# YTM32B1ME1 register map
Vendor: YTMicro; File version: 1.0
CPU: CM33 r0p4, little endian, MPU, FPU, 2 interrupt priority bits
Registers are 32-bit, read-write, reset 0x0 unless marked. A register's access mark holds for its fields unless they carry their own. Offsets are from the block's base; [hi:lo] are bit positions; {n}, {i} and the like mark numbered series; 'fields as' and 'values as' point back to an identical list.

## eTMR0 — Enhanced timer
Base 0x40124000; register names take the prefix eTMR0_
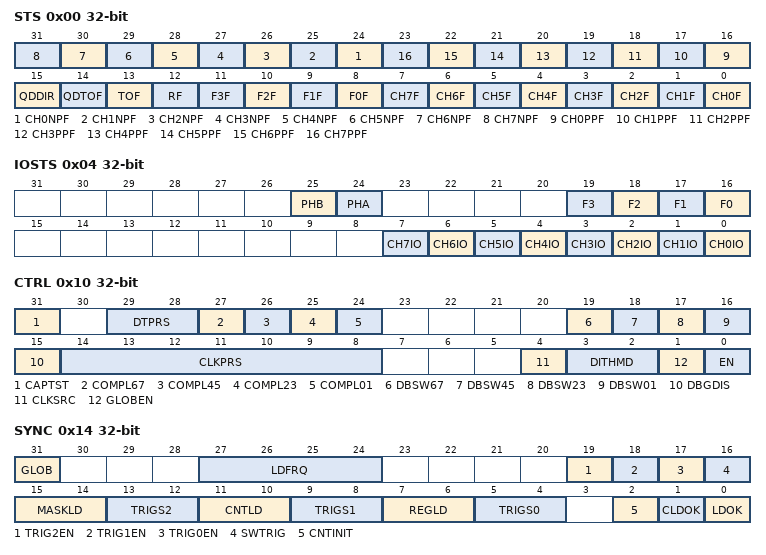
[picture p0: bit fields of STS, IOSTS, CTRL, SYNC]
0x00 STS
  [n+24] CH{n}NPF (n=0..7) — Capture negative pulse ready flag, write 1 to clear this bit.
  [n+16] CH{n}PPF (n=0..7) — Capture positive pulse ready flag, write 1 to clear this bit.
  [15] QDDIR ro — Indicate quadrature decoder counter direction.
    0=Quadrature counter increase; 1=Quadrature counter decrease
  [14] QDTOF — When STS[QDTOF]=1, STS[QDDIR]=0, means quadrature decoder counter increase to QDMOD[QDMOD], then overflow to QDINIT[QDINIT]. When STS[QDTOF]=1, STS[QDDIR]=1, means quadrature decoder counter decrease to QDINIT[QDINIT], then overflow to QDMOD[QDMOD]. Write 1 to clear the bit.
  [13] TOF — Timer overflow flag sets when counter increase from MOD[MOD] to INIT[INIT]. Write 1 to clear the bit.
  [12] RF — Reload flag sets when registers loading occurs. write 1 to clear the bit.
  [n+8] F{n}F (n=0..3) — Fault event {n} occurs flag. Write 1 to clear the bit.
  [n] CH{n}F (n=0..7) — Channel {n} flag is used for capture mode and compare mode. In capture mode, this flag sets when capture event occurs. In compare mode, this flag sets when counter matches the values. Write 1 to clear the bit.
0x04 IOSTS ro
  [25] PHB — Phase B input status is used for Quadrature Decoder. Read-only.
  [24] PHA — Phase A input status is used for Quadrature Decoder. Read-only.
  [n+16] F{n} (n=0..3) — Fault {n} input status is used for fault logic. Read-only.
  [n] CH{n}IO (n=0..7) — In capture mode or common mode, indicate channel {n} input status. In compare mode or PWM mode, indicate channel {n} output status. Read-only.
0x08 CNT
  [31:0] CNT — When CTRL[EN]=0, writing to this register initializes counter according to SYNC[CNTINIT] configuration. When CTRL[EN]=1, reading this register gets the counter value, and writing to this register reloads value from INIT.
0x0C QDCNT ro
  [15:0] QDCNT — Reading this register gets quadrature decoder counter value. The write operation is not valid.
0x10 CTRL
  [31] CAPTST — This bit is used for the capture test.
    0=Capture test is disabled; 1=Capture test is enabled
  [29:28] DTPRS — Clock prescaler for deadtime counter, from 1 to 4.
  [27] COMPL67 — Channel 6 and 7 output independently or complementary in PWM mode.
    0=Independent mode; 1=Complementary mode
  [26] COMPL45 — Channel 4 and 5 output independently or complementary in PWM mode.
    0=Independent mode; 1=Complementary mode
  [25] COMPL23 — Channel 2 and 3 output independently or complementary in PWM mode.
    0=Independent mode; 1=Complementary mode
  [24] COMPL01 — Channel 0 and 1 output independently or complementary in PWM mode.
    0=Independent mode; 1=Complementary mode
  [19] DBSW67 — Channel 6 and 7 is used to generate the double switch signal.
    0=Double switch is disabled; 1=Double switch is enabled
  [18] DBSW45 — Channel 4 and 5 is used to generate the double switch signal.
    0=Double switch is disabled; 1=Double switch is enabled
  [17] DBSW23 — Channel 2 and 3 is used to generate the double switch signal.
    0=Double switch is disabled; 1=Double switch is enabled
  [16] DBSW01 — Channel 0 and 1 is used to generate the double switch signal.
    0=Double switch is disabled; 1=Double switch is enabled
  [15] DBGDIS — Enable/disable the debug mode control.
    0=Counter stops under debug mode; 1=Counter keeps running under debug mode
  [14:8] CLKPRS — Clock prescaler for counter, from 1 to 128.
  [4] CLKSRC — Clock source for counter, bus clock or external clock.
    0=Select bus clock; 1=Select external clock
  [3:2] DITHMD — Select the dithering type in PWM mode.
    0=The dithering mode is disabled; 1=Select period dithering; 2=Select edge dithering; 3=Select period and edge dithering
  [1] GLOBEN — eTMRs counter synchronization mechanisms.
    0=Global logic is disabled; 1=Global logic is enabled. When SYNC[GLOB]=1 from any eTMR includes itself, the counter starts running. When all eTMRs includes itself SYNC[GLOB]=0, the counter stops.
  [0] EN — eTMR enable/disable.
    0=The eTMR is disabled; 1=The eTMR is enabled
0x14 SYNC
  [31] GLOB — Generate global base signal. This bit is used to synchronize with other eTMRs which CTRL[GLOBEN]=1.
    0=Not generate global base signal; 1=Generate global base signal
  [27:24] LDFRQ — Registers Loading occurs at the reloading opportunity that meets this specified frequency.
  [19] TRIG2EN — Enable hardware trigger 2.
    0=Hardware trigger 2 is disabled; 1=Hardware trigger 2 is enabled
  [18] TRIG1EN — Enable hardware trigger 1.
    0=Hardware trigger 1 is disabled; 1=Hardware trigger 1 is enabled
  [17] TRIG0EN — Enable hardware trigger 0.
    0=Hardware trigger 0 is disabled; 1=Hardware trigger 0 is enabled
  [16] SWTRIG wo — Software trigger is used for relevant registers loading. Writing 1 to this bit generates one bus clock cycle pulse trigger. Write-only.
  [15:14] MASKLD — Select loading opportunity for CHMASK register.
    0=Loading together with registers (INIT, MID, MOD, CH_VAL0 and CH_VAL1); 1=Loading occurs when counter matches with MOD[MOD]; 2=Loading occurs when counter matches with MID[MID]; 3=Loading occurs with trigger event which selected by SYNC[TRIGS2]. Any valid hardware trigger x will generate a trigger event (x=0,1,2).
  [13:12] TRIGS2 — Select the loading trigger source for CHMASK register. When selecting hardware trigger, any trigger enabled by SYNC[TRIGxEN] configuratgion is as valid trigger source.
    0=Disable trigger; 1=Select software trigger; 2=Select hardware trigger; 3=Software and hardware trigger are both valid
  [11:10] CNTLD — Select loading opportunity for counter, the counter loads with value from INIT +1.
    0=Loading together with registers (INIT, MID, MOD, CH_VAL0 and CH_VAL1); 1=Loading occurs when counter matches with MID[MID]; 2=Loading occurs with trigger event which selected by SYNC[TRIGS1]. Any valid hardware trigger x will generate a trigger event (x=0,1,2).
  [9:8] TRIGS1 — Select the loading trigger source for counter. When selecting hardware trigger, any trigger enabled by SYNC[TRIGxEN] configuratgion is as valid trigger source.
    values as TRIGS2
  [7:6] REGLD — Select loading opportunity for registers (INIT, MID, MOD, CH_VAL0, CH_VAL1).
    0=Loading is disabled; 1=Loading occurs when counter matches with MOD[MOD]; 2=Loading occurs when counter matches with MID[MID]; 3=Loading occurs with trigger event which selected by SYNC[TRIGS0]. Any valid hardware trigger x will generate a trigger event (x=0,1,2).
  [5:4] TRIGS0 — Select the loading trigger source for registers (INIT, MOD, MID, CH_VAL0, CH_VAL1). When selecting hardware trigger, any trigger enabled by SYNC[TRIGxEN] configuratgion is as valid trigger source.
    values as TRIGS2
  [2] CNTINIT — Before the eTMR enables, select initial value source for counter.
    0=Counter initial value is from register CNT by writing operation; 1=Counter initial value is from register INIT
  [1] CLDOK — Write 1 to this bit to clear SYNC[LDOK], and it automatically clear when SYNC[LDOK]=0.
  [0] LDOK — Set LDOK=1 to indicate registers (INIT, MID, MOD, CH_VAL0, CH_VAL1) loading is ready, it automatically clear when registers loading successfully.
    0=Registers loading is not ready; 1=Registers loading is ready and waits for loading opportunity
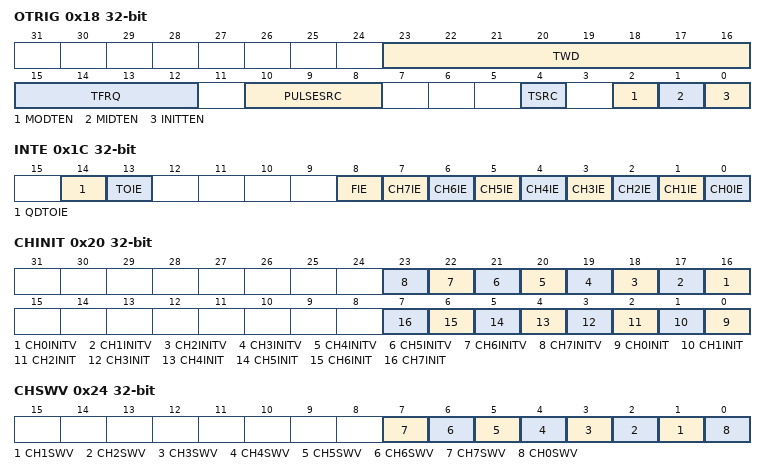
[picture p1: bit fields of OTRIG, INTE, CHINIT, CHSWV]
0x18 OTRIG
  [23:16] TWD — Trigger output width configurable from 1 to 256 bus clock cycles. Default trigger width is 1 bus clock cycle.
  [15:12] TFRQ — Trigger output occurs at the opportunity that meets the specified frequency.
  [10:8] PULSESRC — Select PWM as the pulse-out signal.
    {v}=Select channel {v} PWM as the pulse-out signal (v=0..6); 7=select channel 7 PWM as the pulse-out signal
  [4] TSRC — Trigger output source: matching event occurs or PWM output.
    0=Select trigger that generated by matching event; 1=Select PWM output as the trigger
  [2] MODTEN — Enable/disable the MOD[MOD] matching trigger.
    0=Not generate trigger when counter matches with MOD[MOD]; 1=Generate trigger when counter matches with MOD[MOD]
  [1] MIDTEN — Enable/disable the MID[MID] matching trigger.
    0=Not generate trigger when counter matches with MID[MID]; 1=Generate trigger when counter matches with MID[MID]
  [0] INITTEN — Enable/disable the INIT[INIT] matching trigger.
    0=Not generate trigger when counter matches with INIT[INIT] + 1; 1=Generate trigger when counter matches with INIT[INIT] + 1
0x1C INTE
  [14] QDTOIE — Quadrature decoder timer overflow interrupt enable/disable.
    0=Quadrature decoder timer overflow interrupt is disabled; 1=Quadrature decoder timer overflow interrupt is enabled
  [13] TOIE — Timer overflow interrupt enable/disable.
    0=Timer overflow interrupt is disabled; 1=Timer overflow interrupt is enabled
  [8] FIE — Fault interrupt enable/disable.
    0=Fault interrupt is disabled; 1=Fault interrupt is enabled
  [n] CH{n}IE (n=0..7) — Channel {n} capture/compare interrupt enable/disable.
    0=Channel {n} interrupt is disabled; 1=Channel {n} interrupt is enabled
0x20 CHINIT
  [n+16] CH{n}INITV (n=0..7) — Channel {n} output initial value.
    0=Channel {n} output initial value is 0; 1=Channel {n} output initial value is 1
  [n] CH{n}INIT wo (n=0..7) — Write 1 to this bit to initialize channel output with CHINIT[CH{n}INITV], channel output change with a counter matching event. Write-Only.
    0=Channel {n} output not initial; 1=Channel {n} output initial
0x24 CHSWV
  [n] CH{n}SWV (n=1..7) — Channel {n} output value configured by software.
    0=Channel {n} output value forced to 0 by software; 1=Channel {n} output value forced to 1 by software
  [0] CH0SWV — Channel 0 forced value by software.
    0=Channel 0 output value forced to 0 by software; 1=Channel 0 output value forced to 1 by software
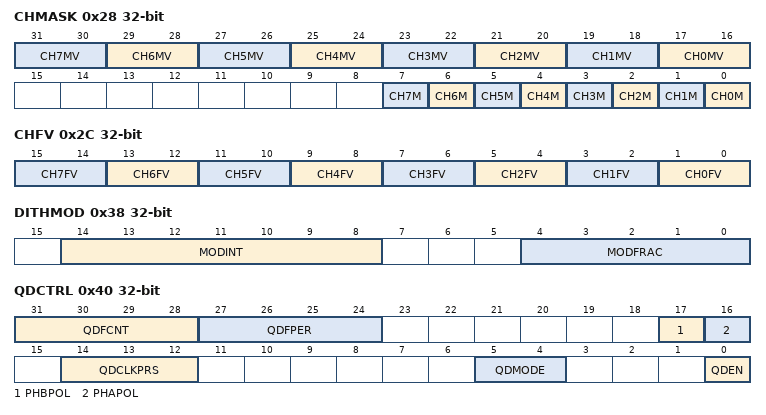
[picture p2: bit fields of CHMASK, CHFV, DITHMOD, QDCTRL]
0x28 CHMASK
  [2n+17:2n+16] CH{n}MV (n=0..7) — Define channel {n} output mask value, it's enabled when CHMASK[CH{n}M]=1.
    0=Channel {n} output mask value is 0; 1=Channel {n} output mask value is 1; 2=Channel {n} output mask value is tri-state; 3=Channel {n} output mask value is tri-state
  [n] CH{n}M (n=0..7) — Channel {n} output mask control used for PWM mode.
    0=Channel {n} output PWM normally; 1=Channel {n} output masked by CHMASK[CH{n}MV]
0x2C CHFV
  [2n+1:2n] CH{n}FV (n=0..7) — Channel {n} forced value when fault event occurs.
    0=Channel {n} output value forced to 0; 1=Channel {n} output value forced to 1; 2=Channel {n} output value forced to tri-state; 3=Channel {n} output value forced to tri-state
0x30 INIT — This register is 32-bit valid in eTMR3, and 16-bit in other instances.
  [31:0] INIT — Counter initial value
0x34 MOD reset 0xFFFF — This register is 32-bit valid in eTMR3, and 16-bit in other instances. Since the counter is 32-bit in eTMR3. The default value is 0xFFFFFFFF in eTMR3, 0x0000FFFF in other eTMRs.
  [31:0] MOD — Counter modulus value.
0x38 DITHMOD
  [14:8] MODINT — The integer part used for period dithering.
  [4:0] MODFRAC — The fractional part used for period dithering.
0x3C MID reset 0xFF — This register is 32-bit valid in eTMR3, and 16-bit in other instances. The default value is 0x0000FFFF in eTMR3, others' are 0x000000FF.
  [31:0] MID — Counter middle value.
0x40 QDCTRL
  [31:28] QDFCNT — Quadrature decoder phase A and phase B input filter sample count, the input is ignored when its valid width was less than QDFCNT x QDFPER.
  [27:24] QDFPER — Quadrature decoder phase A and phase B input filter sample period, the input is ignored when its valid width was less than QDFCNT x QDFPER.
  [17] PHBPOL — Phase B polarity selection.
    0=Not invert phase B input; 1=Invert phase B input
  [16] PHAPOL — Phase A polarity selection.
    0=Not invert phase A input; 1=Invert phase A input
  [14:12] QDCLKPRS — Clock prescaler for quadrature decoder counter.
    0=Divided by 1; 1=Divided by 2; 2=Divided by 4; 3=Divided by 8; 4=Divided by 16; 5=Divided by 32; 6=Divided by 64; 7=Divided by 128
  [5:4] QDMODE — Select decoding mode in the quadrature decoder mode.
    0=Phase A and phase B decoding mode. When phase B changes follow phase A, the counter increases. When phase A changes follow phase B, the counter decreases.; 1=Phase A and phase B decoding mode. When phase A changes follow phase B, the counter increases. When phase B changes follow phase A, the counter decreases.; 2=Counting and direction decoding mode. Phase B input controls direction. When phase B input is high, the counter increases with phase A pulse. When phase B input is low, the counter decreases with phase A pulse.; 3=Counting and direction decoding mode. Phase A input controls direction. When phase A input is high, the counter increases with phase B pulse. When phase A input is low, the counter decreases with phase B pulse.
  [0] QDEN — Quadrature decoder enable/disable.
    0=Quadrature decoder is disabled; 1=Quadrature decoder is enabled
0x44 QDINIT
  [15:0] QDINIT — Quadrature decoder counter initial value.
0x48 QDMOD reset 0xFFFF — The default value is 0x0000FFFF in eTMR1 and eTMR2, others are 0x00000000.
  [15:0] QDMOD — Quadrature decoder counter Modulus value.
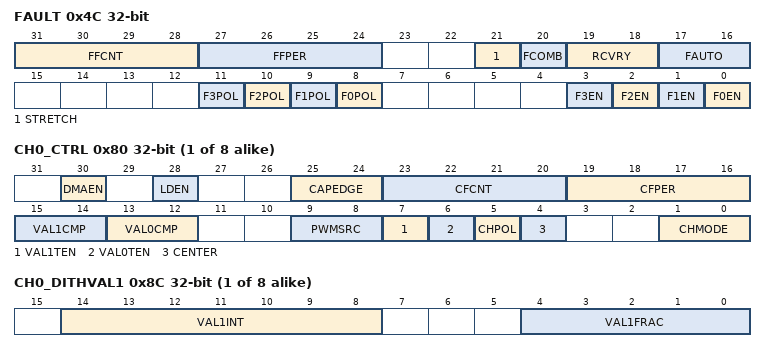
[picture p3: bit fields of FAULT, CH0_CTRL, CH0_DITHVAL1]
0x4C FAULT
  [31:28] FFCNT — Fault input filter sample count, the input is ignored when its valid width was less than FFCNT x FFPER.
  [27:24] FFPER — Fault input filter sample period, the input is ignored when its valid width was less than FFCNT x FFPER.
  [21] STRETCH — Fault input stretch to 2 bus clock cycles width at least.
  [20] FCOMB — When there is no bus clock, the fault event is generated by the combinational logic circuit.
    0=Fault combinational logic disable; 1=Fault combinational logic enable
  [19:18] RCVRY — Select PWM recovery opportunity after fault revoke.
    0=PWM recovery is disabled; 1=PWM can recover when counter matches with MID[MID]; 2=PWM can recover when counter matches with MOD[MOD]; 3=PWM can recover immediately
  [17:16] FAUTO — Select fault automatic recovery mode after the fault event end.
    0=After clearing STS[FxF] flag manually, the fault recovers automatically; 1=The fault recovers immediately, not care STS[FxF] flag; 2=The fault recovers immediately and STS[FxF] flag clear automatically
  [n+8] F{n}POL (n=0..3) — Fault {n} input polarity selection.
    0=High level signal is regarded as fault signal; 1=Invert fault {n} input. Low level signal is regarded as fault signal.
  [n] F{n}EN (n=0..3) — Fault {n} enable.
    0=Fault {n} disable; 1=Fault {n} enable
{0x80+0x40*i} CH{i}_CTRL (i=0..7)
  [30] DMAEN — DMA enable/disable for compare/capture mode.
    0=DMA is disabled; 1=DMA is enabled
  [28] LDEN — Current channel registers (CH_VAL0/CH_VAL1) loading enable/disable.
    0=Registers Loading is disabled; 1=Registers Loading is enabled
  [25:24] CAPEDGE — Select the capture edge in the input capture mode.
    0=Capture is disabled; 1=Capture rising edge; 2=Capture falling edge; 3=Capture both rising edge and falling edge
  [23:20] CFCNT — Capture input filter sample counter, the input is ignored when its valid width was less than CFCNT x CFPER.
  [19:16] CFPER — Capture input filter sample period, the input is ignored when its valid width was less than CFCNT x CFPER.
  [15:14] VAL1CMP — Select the output value when counter matches with CH_VAL1[VAL1] in compare mode.
    0=Output value 0 when counter matches with CH_VAL1[VAL1]; 1=Output value 1 when counter matches with CH_VAL1[VAL1]; 2=Output toggle when counter matches with CH_VAL1[VAL1]
  [13:12] VAL0CMP — Select the output value when counter matches with CH_VAL0[VAL0] in compare mode.
    0=Output value 0 when counter matches with CH_VAL0[VAL0]; 1=Output value 1 when counter matches with CH_VAL0[VAL0]; 2=Output toggle when counter matches with CH_VAL0[VAL0]
  [9:8] PWMSRC — Select PWM generation source in PWM mode.
    0=Normal mode, PWM is generated by VAL0 and VAL1; 1=Invert mode, invert the PWM in normal mode; 2=Software mode, PWM is generated by CHSWV register
  [7] VAL1TEN — Enable/disable generating trigger when counter matches with CH_VAL1[VAL1].
    0=Not generate trigger when counter matches with CH_VAL1[VAL1]; 1=Generate trigger when counter matches with CH_VAL1[VAL1]
  [6] VAL0TEN — Enable/disable generating trigger when counter matches with CH_VAL0[VAL0].
    0=Not generate trigger when counter matches with CH_VAL0[VAL0]; 1=Generate trigger when counter matches with CH_VAL0[VAL0]
  [5] CHPOL — Channel output polarity control.
    0=Not invert the channel output; 1=Invert the channel output
  [4] CENTER — Center aligned PWM generate when center aligned mode enabled.
    0=Center aligned mode disabled; 1=Center aligned mode enabled
  [1:0] CHMODE — Select channel mode.
    0=Common timer; 1=PWM mode; 2=Compare mode; 3=Capture mode
{0x84+0x40*i} CH{i}_VAL0 (i=0..7) — This register is 32-bit valid in eTMR3. Other eTMRs are 16-bit valid.
  [31:0] VAL0 — Define the value 0.
{0x88+0x40*i} CH{i}_VAL1 (i=0..7) — This register is 32-bit valid in eTMR3. Other eTMRs are 16-bit valid.
  [31:0] VAL1 — Define the value 1.
{0x8C+0x40*i} CH{i}_DITHVAL1 (i=0..7)
  [14:8] VAL1INT — The integer part used for duty cycle dithering.
  [4:0] VAL1FRAC — The fractional part used for duty cycle dithering.
{0x90+0x40*i} CH{i}_DT (i=0..7)
  [15:0] DTVAL — Deatime value used in complementary mode.
{0x94+0x40*i} CH{i}_CVAL ro (i=0..7) — This register is 32-bit valid in eTMR3. Other eTMRs are 16-bit valid.
  [31:0] CVAL — In capture mode, store counter value when a capture event occurs.
{0x98+0x40*i} CH{i}_PPCNTN ro (i=0..7) — This register is 32-bit valid in eTMR3, other eTMRs are 16-bit valid.
  [7:0] PPCNTN — Positive pulse width measurement counter period number.
{0x9C+0x40*i} CH{i}_PPCNTV ro (i=0..7) — This register is 32-bit valid in eTMR3, other eTMRs are 16-bit valid.
  [31:0] PPCNTV — Positive pulse width measurement capture counter value.
{0xA0+0x40*i} CH{i}_NPCNTN ro (i=0..7) — This register is 32-bit valid in eTMR3, other eTMRs are 16-bit valid.
  [7:0] NPCNTN — Negative pulse width measurement counter period number.
{0xA4+0x40*i} CH{i}_NPCNTV ro (i=0..7) — This register is 32-bit valid in eTMR3, other eTMRs are 16-bit valid.
  [31:0] NPCNTV — Negative pulse width measurement capture counter value.

## eTMR1 — Enhanced timer
Base 0x40128000; register names take the prefix eTMR1_
Registers as eTMR0; these are added or differ:
0x48 QDMOD reset 0xFFFF — The default value is 0x0000FFFF in eTMR1 and eTMR2, others are 0x00000000.
  [15:0] QDMOD — Quadrature decoder counter Modulus value.

## eTMR2 — Enhanced timer
Base 0x4012C000; register names take the prefix eTMR2_
Registers as eTMR0; these are added or differ:
0x48 QDMOD reset 0xFFFF — The default value is 0x0000FFFF in eTMR1 and eTMR2, others are 0x00000000.
  [15:0] QDMOD — Quadrature decoder counter Modulus value.

## eTMR3 — Enhanced timer
Base 0x40130000; register names take the prefix eTMR3_
Registers as eTMR0; these are added or differ:
0x30 INIT — This register is 32-bit valid in eTMR3, and 16-bit in other instances.
  [31:0] INIT — Counter initial value
0x34 MOD reset 0xFFFF — This register is 32-bit valid in eTMR3, and 16-bit in other instances. Since the counter is 32-bit in eTMR3. The default value is 0xFFFFFFFF in eTMR3, 0x0000FFFF in other eTMRs.
  [31:0] MOD — Counter modulus value.
0x3C MID reset 0xFF — This register is 32-bit valid in eTMR3, and 16-bit in other instances. The default value is 0x0000FFFF in eTMR3, others' are 0x000000FF.
  [31:0] MID — Counter middle value.
{0x84+0x40*i} CH{i}_VAL0 (i=0..7) — This register is 32-bit valid in eTMR3. Other eTMRs are 16-bit valid.
  [31:0] VAL0 — Define the value 0.
{0x88+0x40*i} CH{i}_VAL1 (i=0..7) — This register is 32-bit valid in eTMR3. Other eTMRs are 16-bit valid.
  [31:0] VAL1 — Define the value 1.
{0x94+0x40*i} CH{i}_CVAL ro (i=0..7) — This register is 32-bit valid in eTMR3. Other eTMRs are 16-bit valid.
  [31:0] CVAL — In capture mode, store counter value when a capture event occurs.
{0x98+0x40*i} CH{i}_PPCNTN ro (i=0..7) — This register is 32-bit valid in eTMR3, other eTMRs are 16-bit valid.
  [7:0] PPCNTN — Positive pulse width measurement counter period number.
{0x9C+0x40*i} CH{i}_PPCNTV ro (i=0..7) — This register is 32-bit valid in eTMR3, other eTMRs are 16-bit valid.
  [31:0] PPCNTV — Positive pulse width measurement capture counter value.
{0xA0+0x40*i} CH{i}_NPCNTN ro (i=0..7) — This register is 32-bit valid in eTMR3, other eTMRs are 16-bit valid.
  [7:0] NPCNTN — Negative pulse width measurement counter period number.
{0xA4+0x40*i} CH{i}_NPCNTV ro (i=0..7) — This register is 32-bit valid in eTMR3, other eTMRs are 16-bit valid.
  [31:0] NPCNTV — Negative pulse width measurement capture counter value.
